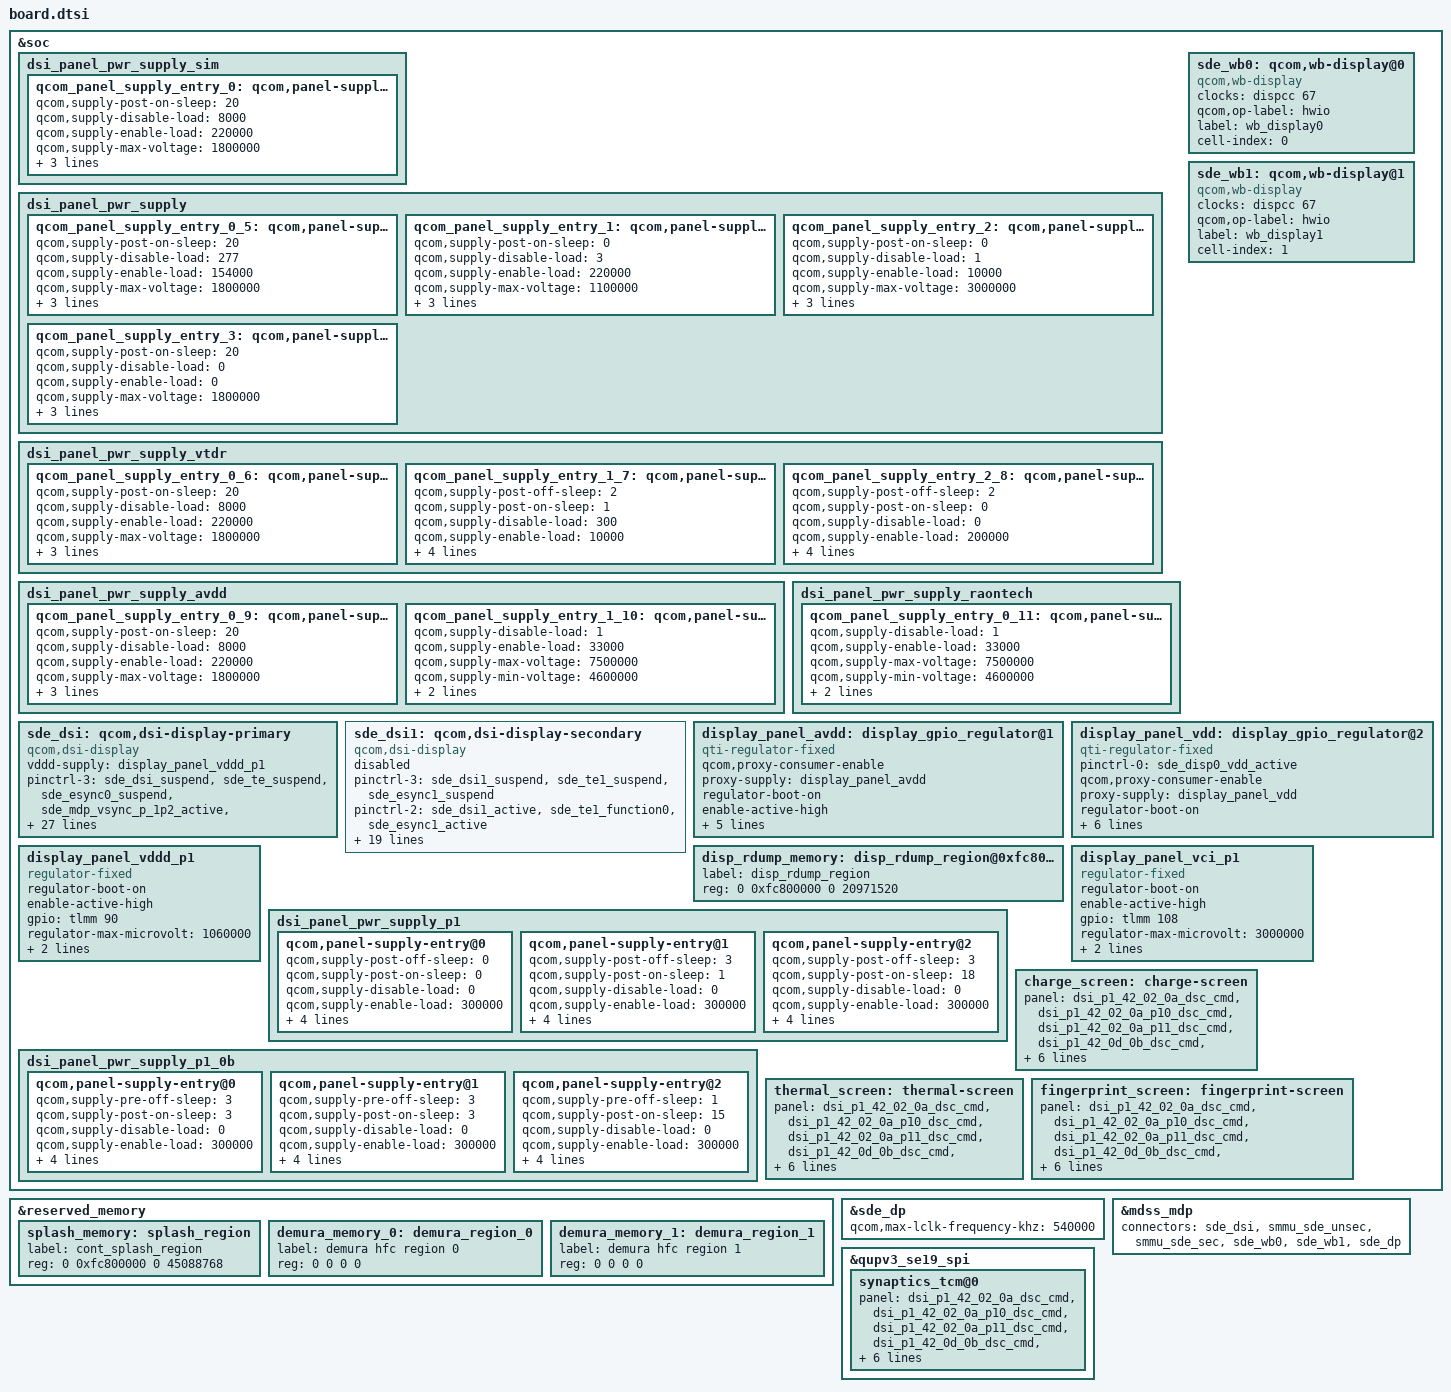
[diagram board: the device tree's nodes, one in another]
/* Xiaomi 17 Ultra panel configuration, OS4.0.7.0.XPACNXM. */

#include "pins.dtsi"
#include "nt37801-amoled-fhd-plus-cmd.dtsi"
#include "p1-42-02-0a-dsc-cmd.dtsi"
#include "p1-42-02-0a-p10-dsc-cmd.dtsi"
#include "p1-42-02-0a-p11-dsc-cmd.dtsi"
#include "p1-42-0d-0b-dsc-cmd.dtsi"
#include "p1-42-0d-0b-p10-dsc-cmd.dtsi"
#include "p1-42-0d-0b-p11-dsc-cmd.dtsi"
#include "p1-42-0d-0b-p12-dsc-cmd.dtsi"
#include "p1-42-0d-0b-p2-dsc-cmd.dtsi"
#include "p1-42-0d-0b-p21-dsc-cmd.dtsi"

&soc {
	dsi_panel_pwr_supply_sim: dsi_panel_pwr_supply_sim {
		#size-cells = <0>;
		#address-cells = <1>;

		qcom_panel_supply_entry_0: qcom,panel-supply-entry@0 {
			qcom,supply-post-on-sleep = <20>;
			qcom,supply-disable-load = <8000>;
			qcom,supply-enable-load = <220000>;
			qcom,supply-max-voltage = <1800000>;
			qcom,supply-min-voltage = <1800000>;
			qcom,supply-name = "dummy";
			reg = <0>;
		};
	};

	dsi_panel_pwr_supply: dsi_panel_pwr_supply {
		#size-cells = <0>;
		#address-cells = <1>;

		qcom_panel_supply_entry_0_5: qcom,panel-supply-entry@0 {
			qcom,supply-post-on-sleep = <20>;
			qcom,supply-disable-load = <277>;
			qcom,supply-enable-load = <154000>;
			qcom,supply-max-voltage = <1800000>;
			qcom,supply-min-voltage = <1800000>;
			qcom,supply-name = "vddio";
			reg = <0>;
		};

		qcom_panel_supply_entry_1: qcom,panel-supply-entry@1 {
			qcom,supply-post-on-sleep = <0>;
			qcom,supply-disable-load = <3>;
			qcom,supply-enable-load = <220000>;
			qcom,supply-max-voltage = <1100000>;
			qcom,supply-min-voltage = <1045000>;
			qcom,supply-name = "vdd";
			reg = <1>;
		};

		qcom_panel_supply_entry_2: qcom,panel-supply-entry@2 {
			qcom,supply-post-on-sleep = <0>;
			qcom,supply-disable-load = <1>;
			qcom,supply-enable-load = <10000>;
			qcom,supply-max-voltage = <3000000>;
			qcom,supply-min-voltage = <3000000>;
			qcom,supply-name = "vci";
			reg = <2>;
		};

		qcom_panel_supply_entry_3: qcom,panel-supply-entry@3 {
			qcom,supply-post-on-sleep = <20>;
			qcom,supply-disable-load = <0>;
			qcom,supply-enable-load = <0>;
			qcom,supply-max-voltage = <1800000>;
			qcom,supply-min-voltage = <1800000>;
			qcom,supply-name = "tvdd";
			reg = <3>;
		};
	};

	dsi_panel_pwr_supply_vtdr: dsi_panel_pwr_supply_vtdr {
		#size-cells = <0>;
		#address-cells = <1>;

		qcom_panel_supply_entry_0_6: qcom,panel-supply-entry@0 {
			qcom,supply-post-on-sleep = <20>;
			qcom,supply-disable-load = <8000>;
			qcom,supply-enable-load = <220000>;
			qcom,supply-max-voltage = <1800000>;
			qcom,supply-min-voltage = <1800000>;
			qcom,supply-name = "vddio";
			reg = <0>;
		};

		qcom_panel_supply_entry_1_7: qcom,panel-supply-entry@1 {
			qcom,supply-post-off-sleep = <2>;
			qcom,supply-post-on-sleep = <1>;
			qcom,supply-disable-load = <300>;
			qcom,supply-enable-load = <10000>;
			qcom,supply-max-voltage = <3000000>;
			qcom,supply-min-voltage = <3000000>;
			qcom,supply-name = "vci";
			reg = <1>;
		};

		qcom_panel_supply_entry_2_8: qcom,panel-supply-entry@2 {
			qcom,supply-post-off-sleep = <2>;
			qcom,supply-post-on-sleep = <0>;
			qcom,supply-disable-load = <0>;
			qcom,supply-enable-load = <200000>;
			qcom,supply-max-voltage = <1292000>;
			qcom,supply-min-voltage = <1200000>;
			qcom,supply-name = "vdd";
			reg = <2>;
		};
	};

	dsi_panel_pwr_supply_avdd: dsi_panel_pwr_supply_avdd {
		#size-cells = <0>;
		#address-cells = <1>;

		qcom_panel_supply_entry_0_9: qcom,panel-supply-entry@0 {
			qcom,supply-post-on-sleep = <20>;
			qcom,supply-disable-load = <8000>;
			qcom,supply-enable-load = <220000>;
			qcom,supply-max-voltage = <1800000>;
			qcom,supply-min-voltage = <1800000>;
			qcom,supply-name = "vddio";
			reg = <0>;
		};

		qcom_panel_supply_entry_1_10: qcom,panel-supply-entry@1 {
			qcom,supply-disable-load = <1>;
			qcom,supply-enable-load = <33000>;
			qcom,supply-max-voltage = <7500000>;
			qcom,supply-min-voltage = <4600000>;
			qcom,supply-name = "avdd";
			reg = <1>;
		};
	};

	dsi_panel_pwr_supply_raontech: dsi_panel_pwr_supply_raontech {
		#size-cells = <0>;
		#address-cells = <1>;

		qcom_panel_supply_entry_0_11: qcom,panel-supply-entry@0 {
			qcom,supply-disable-load = <1>;
			qcom,supply-enable-load = <33000>;
			qcom,supply-max-voltage = <7500000>;
			qcom,supply-min-voltage = <4600000>;
			qcom,supply-name = "avdd";
			reg = <0>;
		};
	};

	sde_dsi: qcom,dsi-display-primary {
		vddd-supply = <&display_panel_vddd_p1>;
		pinctrl-3 = <&sde_dsi_suspend>,
			<&sde_te_suspend>,
			<&sde_esync0_suspend>,
			<&sde_mdp_vsync_p_1p2_active>,
			<&sde_mdp_vsync_p_1p8_active>,
			<&sde_disp0_rst_1p2_active>,
			<&sde_disp0_rst_1p8_active>;
		pinctrl-2 = <&sde_dsi_active>,
			<&sde_te_function0>,
			<&sde_esync0_active>,
			<&sde_mdp_vsync_p_1p2_active>,
			<&sde_mdp_vsync_p_1p8_active>,
			<&sde_disp0_rst_1p2_active>,
			<&sde_disp0_rst_1p8_active>;
		pinctrl-1 = <&sde_dsi_suspend>,
			<&sde_te_suspend>;
		pinctrl-0 = <&sde_dsi_active>,
			<&sde_te_active>;
		pinctrl-names = "panel_active", "panel_suspend";
		vdd-supply = <&L11B>;
		vci-supply = <&display_panel_vci_p1>;
		vddio-supply = <&L12B>;
		clock-names = "pll_byte_clk0",
			"pll_dsi_clk0",
			"pll_byte_clk1",
			"pll_dsi_clk1",
			"mdp_core_clk",
			"esync_clk_rcg";
		clocks = <&mdss_dsi_phy0 0>,
			<&mdss_dsi_phy0 1>,
			<&mdss_dsi_phy1 0>,
			<&mdss_dsi_phy1 1>,
			<&dispcc 67>,
			<&dispcc 1>;
		qcom,demura-panel-id = <19064576 1137>;
		qcom,dsi-default-panel = <&dsi_p1_42_02_0a_dsc_cmd>;
		qcom,mdp = <&mdss_mdp>;
		qcom,panel-te-source = <0>;
		qcom,platform-te-gpio = <&tlmm 86 0>;
		qcom,dsi-phy = <&mdss_dsi_phy0>,
			<&mdss_dsi_phy1>;
		qcom,dsi-ctrl = <&mdss_dsi0>,
			<&mdss_dsi1>;
		status = "ok";
		qcom,op-label = "hwio";
		label = "primary";
		compatible = "qcom,dsi-display";
	};

	sde_dsi1: qcom,dsi-display-secondary {
		pinctrl-3 = <&sde_dsi1_suspend>,
			<&sde_te1_suspend>,
			<&sde_esync1_suspend>;
		pinctrl-2 = <&sde_dsi1_active>,
			<&sde_te1_function0>,
			<&sde_esync1_active>;
		pinctrl-1 = <&sde_dsi1_active>,
			<&sde_te1_active>,
			<&sde_esync1_active>;
		pinctrl-0 = <&sde_dsi1_active>,
			<&sde_te1_active>,
			<&sde_esync1_suspend>;
		pinctrl-names = "panel_active",
			"panel_active_with_esync",
			"panel_active_with_esync_without_te",
			"panel_suspend";
		tvdd-supply = <&L4B>;
		vdd-supply = <&L11B>;
		vci-supply = <&L13B>;
		vddio-supply = <&L12B>;
		clock-names = "pll_byte_clk0",
			"pll_dsi_clk0",
			"pll_byte_clk1",
			"pll_dsi_clk1",
			"mdp_core_clk",
			"esync_clk_rcg";
		clocks = <&mdss_dsi_phy0 0>,
			<&mdss_dsi_phy0 1>,
			<&mdss_dsi_phy1 0>,
			<&mdss_dsi_phy1 1>,
			<&dispcc 67>,
			<&dispcc 3>;
		qcom,demura-panel-id = <0 0>;
		qcom,mdp = <&mdss_mdp>;
		qcom,panel-te-source = <1>;
		qcom,platform-te-gpio = <&tlmm 87 0>;
		qcom,dsi-phy = <&mdss_dsi_phy0>,
			<&mdss_dsi_phy1>;
		qcom,dsi-ctrl = <&mdss_dsi0>,
			<&mdss_dsi1>;
		status = "disabled";
		qcom,op-label = "hwio";
		label = "secondary";
		compatible = "qcom,dsi-display";
	};
};

&soc {
	sde_wb0: qcom,wb-display@0 {
		clock-names = "mdp_core_clk";
		clocks = <&dispcc 67>;
		status = "ok";
		qcom,op-label = "hwio";
		label = "wb_display0";
		cell-index = <0>;
		compatible = "qcom,wb-display";
	};

	sde_wb1: qcom,wb-display@1 {
		clock-names = "mdp_core_clk";
		clocks = <&dispcc 67>;
		status = "ok";
		qcom,op-label = "hwio";
		label = "wb_display1";
		cell-index = <1>;
		compatible = "qcom,wb-display";
	};

	display_panel_avdd: display_gpio_regulator@1 {
		pinctrl-names = "default";
		qcom,proxy-consumer-enable;
		proxy-supply = <&display_panel_avdd>;
		regulator-boot-on;
		enable-active-high;
		gpio = <&pmh0104_gpios 7 0>;
		regulator-enable-ramp-delay = <233>;
		regulator-max-microvolt = <5500000>;
		regulator-min-microvolt = <5500000>;
		regulator-name = "display_panel_avdd";
		compatible = "qti-regulator-fixed";
	};

	display_panel_vdd: display_gpio_regulator@2 {
		pinctrl-0 = <&sde_disp0_vdd_active>;
		pinctrl-names = "default";
		qcom,proxy-consumer-enable;
		proxy-supply = <&display_panel_vdd>;
		regulator-boot-on;
		enable-active-high;
		gpio = <&pmd802x_gpios 2 0>;
		regulator-enable-ramp-delay = <233>;
		regulator-max-microvolt = <1100000>;
		regulator-min-microvolt = <1100000>;
		regulator-name = "display_panel_vdd";
		compatible = "qti-regulator-fixed";
	};

	disp_rdump_memory: disp_rdump_region@0xfc800000 {
		label = "disp_rdump_region";
		reg = <0 0xfc800000 0 20971520>;
	};
};

&reserved_memory {
	splash_memory: splash_region {
		label = "cont_splash_region";
		reg = <0 0xfc800000 0 45088768>;
	};

	demura_memory_0: demura_region_0 {
		label = "demura hfc region 0";
		reg = <0 0 0 0>;
	};

	demura_memory_1: demura_region_1 {
		label = "demura hfc region 1";
		reg = <0 0 0 0>;
	};
};

&soc {
	display_panel_vddd_p1: display_panel_vddd_p1 {
		regulator-boot-on;
		enable-active-high;
		gpio = <&tlmm 90 0>;
		regulator-max-microvolt = <1060000>;
		regulator-min-microvolt = <1060000>;
		regulator-name = "display_panel_vddd_p1";
		compatible = "regulator-fixed";
	};

	display_panel_vci_p1: display_panel_vci_p1 {
		regulator-boot-on;
		enable-active-high;
		gpio = <&tlmm 108 0>;
		regulator-max-microvolt = <3000000>;
		regulator-min-microvolt = <3000000>;
		regulator-name = "display_panel_vci_p1";
		compatible = "regulator-fixed";
	};

	dsi_panel_pwr_supply_p1: dsi_panel_pwr_supply_p1 {
		qcom,panel-supply-entry@0 {
			qcom,supply-post-off-sleep = <0>;
			qcom,supply-post-on-sleep = <0>;
			qcom,supply-disable-load = <0>;
			qcom,supply-enable-load = <300000>;
			qcom,supply-max-voltage = <1800000>;
			qcom,supply-min-voltage = <1800000>;
			qcom,supply-name = "vddio";
			reg = <0>;
		};

		qcom,panel-supply-entry@1 {
			qcom,supply-post-off-sleep = <3>;
			qcom,supply-post-on-sleep = <1>;
			qcom,supply-disable-load = <0>;
			qcom,supply-enable-load = <300000>;
			qcom,supply-max-voltage = <1060000>;
			qcom,supply-min-voltage = <1060000>;
			qcom,supply-name = "vddd";
			reg = <1>;
		};

		qcom,panel-supply-entry@2 {
			qcom,supply-post-off-sleep = <3>;
			qcom,supply-post-on-sleep = <18>;
			qcom,supply-disable-load = <0>;
			qcom,supply-enable-load = <300000>;
			qcom,supply-max-voltage = <3000000>;
			qcom,supply-min-voltage = <3000000>;
			qcom,supply-name = "vci";
			reg = <2>;
		};
	};

	dsi_panel_pwr_supply_p1_0b: dsi_panel_pwr_supply_p1_0b {
		qcom,panel-supply-entry@0 {
			qcom,supply-pre-off-sleep = <3>;
			qcom,supply-post-on-sleep = <3>;
			qcom,supply-disable-load = <0>;
			qcom,supply-enable-load = <300000>;
			qcom,supply-max-voltage = <1800000>;
			qcom,supply-min-voltage = <1800000>;
			qcom,supply-name = "vddio";
			reg = <0>;
		};

		qcom,panel-supply-entry@1 {
			qcom,supply-pre-off-sleep = <3>;
			qcom,supply-post-on-sleep = <3>;
			qcom,supply-disable-load = <0>;
			qcom,supply-enable-load = <300000>;
			qcom,supply-max-voltage = <3000000>;
			qcom,supply-min-voltage = <3000000>;
			qcom,supply-name = "vci";
			reg = <1>;
		};

		qcom,panel-supply-entry@2 {
			qcom,supply-pre-off-sleep = <1>;
			qcom,supply-post-on-sleep = <15>;
			qcom,supply-disable-load = <0>;
			qcom,supply-enable-load = <300000>;
			qcom,supply-max-voltage = <1060000>;
			qcom,supply-min-voltage = <1060000>;
			qcom,supply-name = "vddd";
			reg = <2>;
		};
	};
};

&sde_dp {
	status = "ok";
	qcom,max-lclk-frequency-khz = <540000>;
};

&mdss_mdp {
	connectors = <&sde_dsi>,
		<&smmu_sde_unsec>,
		<&smmu_sde_sec>,
		<&sde_wb0>,
		<&sde_wb1>,
		<&sde_dp>;
};

&qupv3_se19_spi {
	synaptics_tcm@0 {
		panel = <&dsi_p1_42_02_0a_dsc_cmd>,
			<&dsi_p1_42_02_0a_p10_dsc_cmd>,
			<&dsi_p1_42_02_0a_p11_dsc_cmd>,
			<&dsi_p1_42_0d_0b_dsc_cmd>,
			<&dsi_p1_42_0d_0b_p10_dsc_cmd>,
			<&dsi_p1_42_0d_0b_p11_dsc_cmd>,
			<&dsi_p1_42_0d_0b_p12_dsc_cmd>,
			<&dsi_p1_42_0d_0b_p2_dsc_cmd>,
			<&dsi_p1_42_0d_0b_p21_dsc_cmd>,
			<&dsi_nt37801_amoled_fhd_plus_cmd>;
	};
};

&soc {
	charge_screen: charge-screen {
		panel = <&dsi_p1_42_02_0a_dsc_cmd>,
			<&dsi_p1_42_02_0a_p10_dsc_cmd>,
			<&dsi_p1_42_02_0a_p11_dsc_cmd>,
			<&dsi_p1_42_0d_0b_dsc_cmd>,
			<&dsi_p1_42_0d_0b_p10_dsc_cmd>,
			<&dsi_p1_42_0d_0b_p11_dsc_cmd>,
			<&dsi_p1_42_0d_0b_p12_dsc_cmd>,
			<&dsi_p1_42_0d_0b_p2_dsc_cmd>,
			<&dsi_p1_42_0d_0b_p21_dsc_cmd>,
			<&dsi_nt37801_amoled_fhd_plus_cmd>;
	};

	thermal_screen: thermal-screen {
		panel = <&dsi_p1_42_02_0a_dsc_cmd>,
			<&dsi_p1_42_02_0a_p10_dsc_cmd>,
			<&dsi_p1_42_02_0a_p11_dsc_cmd>,
			<&dsi_p1_42_0d_0b_dsc_cmd>,
			<&dsi_p1_42_0d_0b_p10_dsc_cmd>,
			<&dsi_p1_42_0d_0b_p11_dsc_cmd>,
			<&dsi_p1_42_0d_0b_p12_dsc_cmd>,
			<&dsi_p1_42_0d_0b_p2_dsc_cmd>,
			<&dsi_p1_42_0d_0b_p21_dsc_cmd>,
			<&dsi_nt37801_amoled_fhd_plus_cmd>;
	};

	fingerprint_screen: fingerprint-screen {
		panel = <&dsi_p1_42_02_0a_dsc_cmd>,
			<&dsi_p1_42_02_0a_p10_dsc_cmd>,
			<&dsi_p1_42_02_0a_p11_dsc_cmd>,
			<&dsi_p1_42_0d_0b_dsc_cmd>,
			<&dsi_p1_42_0d_0b_p10_dsc_cmd>,
			<&dsi_p1_42_0d_0b_p11_dsc_cmd>,
			<&dsi_p1_42_0d_0b_p12_dsc_cmd>,
			<&dsi_p1_42_0d_0b_p2_dsc_cmd>,
			<&dsi_p1_42_0d_0b_p21_dsc_cmd>,
			<&dsi_nt37801_amoled_fhd_plus_cmd>;
	};
};
